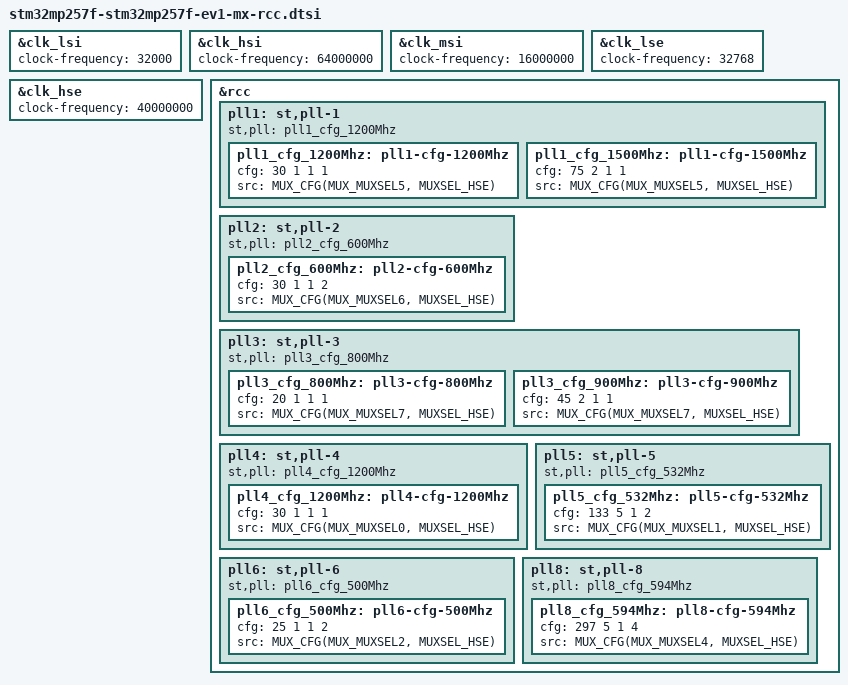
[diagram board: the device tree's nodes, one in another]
// SPDX-License-Identifier: (GPL-2.0-or-later OR BSD-3-Clause)
/*
 * Copyright (C) 2024, STMicroelectronics - All Rights Reserved
 * Author: STM32CubeMX code generation for STMicroelectronics.
 */

/* For more information on Device Tree configuration, please refer to
 * https://wiki.st.com/stm32mpu/wiki/Category:Device_tree_configuration
 */

&clk_lsi {
	clock-frequency = <32000>;

	/* USER CODE BEGIN clk_lsi */
	/* USER CODE END clk_lsi */
};
&clk_hsi {
	clock-frequency = <64000000>;

	/* USER CODE BEGIN clk_hsi */
	/* USER CODE END clk_hsi */
};
&clk_msi {
	clock-frequency = <16000000>;

	/* USER CODE BEGIN clk_msi */
	/* USER CODE END clk_msi */
};
&clk_lse {
	clock-frequency = <32768>;

	/* USER CODE BEGIN clk_lse */
	/* USER CODE END clk_lse */
};
&clk_hse {
	clock-frequency = <40000000>;

	/* USER CODE BEGIN clk_hse */
	/* USER CODE END clk_hse */
};

&rcc{

	pll1:st,pll-1 {
		st,pll = < &pll1_cfg_1200Mhz >;

		pll1_cfg_1200Mhz: pll1-cfg-1200Mhz{
			cfg = <30 1 1 1>;
			src = <MUX_CFG(MUX_MUXSEL5, MUXSEL_HSE)>;
		};
		/* USER CODE BEGIN pll1 */
		pll1_cfg_1500Mhz: pll1-cfg-1500Mhz {
			cfg = <75 2 1 1>;
			src = <MUX_CFG(MUX_MUXSEL5, MUXSEL_HSE)>;
		};
		/* USER CODE END pll1 */
	};

	pll2:st,pll-2 {
		st,pll = < &pll2_cfg_600Mhz >;

		pll2_cfg_600Mhz: pll2-cfg-600Mhz{
			cfg = <30 1 1 2>;
			src = <MUX_CFG(MUX_MUXSEL6, MUXSEL_HSE)>;
		};
		/* USER CODE BEGIN pll2 */
		/* USER CODE END pll2 */
	};

	pll3:st,pll-3 {
		st,pll = < &pll3_cfg_800Mhz >;

		pll3_cfg_800Mhz: pll3-cfg-800Mhz{
			cfg = <20 1 1 1>;
			src = <MUX_CFG(MUX_MUXSEL7, MUXSEL_HSE)>;
		};
		/* USER CODE BEGIN pll3 */
		pll3_cfg_900Mhz: pll3-cfg-900Mhz {
			cfg = <45 2 1 1>;
			src = <MUX_CFG(MUX_MUXSEL7, MUXSEL_HSE)>;
		};
		/* USER CODE END pll3 */
	};

	pll4:st,pll-4 {
		st,pll = < &pll4_cfg_1200Mhz >;

		pll4_cfg_1200Mhz: pll4-cfg-1200Mhz{
			cfg = <30 1 1 1>;
			src = <MUX_CFG(MUX_MUXSEL0, MUXSEL_HSE)>;
		};
		/* USER CODE BEGIN pll4 */
		/* USER CODE END pll4 */
	};

	pll5:st,pll-5 {
		st,pll = < &pll5_cfg_532Mhz >;

		pll5_cfg_532Mhz: pll5-cfg-532Mhz{
			cfg = <133 5 1 2>;
			src = <MUX_CFG(MUX_MUXSEL1, MUXSEL_HSE)>;
		};
		/* USER CODE BEGIN pll5 */
		/* USER CODE END pll5 */
	};

	pll6:st,pll-6 {
		st,pll = < &pll6_cfg_500Mhz >;

		pll6_cfg_500Mhz: pll6-cfg-500Mhz{
			cfg = <25 1 1 2>;
			src = <MUX_CFG(MUX_MUXSEL2, MUXSEL_HSE)>;
		};
		/* USER CODE BEGIN pll6 */
		/* USER CODE END pll6 */
	};

	pll8:st,pll-8 {
		st,pll = < &pll8_cfg_594Mhz >;

		pll8_cfg_594Mhz: pll8-cfg-594Mhz{
			cfg = <297 5 1 4>;
			src = <MUX_CFG(MUX_MUXSEL4, MUXSEL_HSE)>;
		};
		/* USER CODE BEGIN pll8 */
		/* USER CODE END pll8 */
	};

	/* USER CODE BEGIN rcc */
	/* USER CODE END rcc */
};
